# MSS_CTRL_MSS_CTRL register map
Vendor: Texas Instruments
Registers are 32-bit, read-only, reset 0x0 unless marked. A register's access mark holds for its fields unless they carry their own. Offsets are as the file gives them; [hi:lo] are bit positions; {n}, {i} and the like mark numbered series; 'fields as' and 'values as' point back to an identical list.

## MSS_CTRL_MSS_CTRL (part 2 of 5)
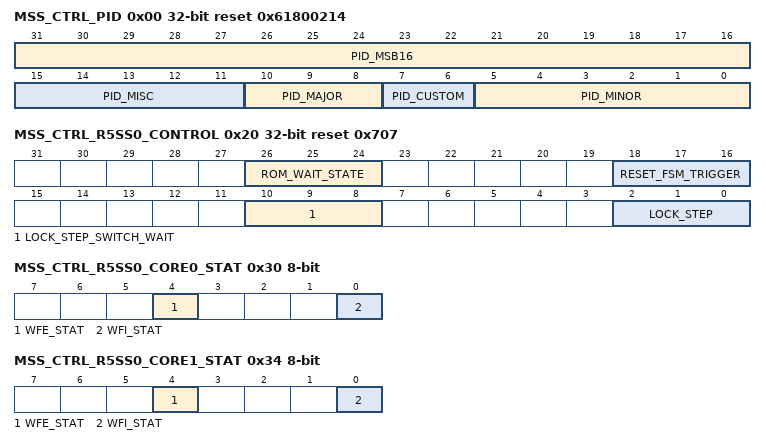
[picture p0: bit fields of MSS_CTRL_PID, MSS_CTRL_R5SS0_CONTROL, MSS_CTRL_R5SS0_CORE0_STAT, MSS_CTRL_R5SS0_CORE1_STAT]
0x00 MSS_CTRL_PID reset 0x61800214
  [31:16] PID_MSB16 — Not Defined
  [15:11] PID_MISC — Not Defined
  [10:8] PID_MAJOR — Not Defined
  [7:6] PID_CUSTOM — Not Defined
  [5:0] PID_MINOR — Not Defined
0x20 MSS_CTRL_R5SS0_CONTROL rw reset 0x707
  [26:24] ROM_WAIT_STATE — writing '111' enables a single cycle wait state with respect to CR5A_clk for rom access.This needs to be set when R5 clock is at 400MHZ and Interconnect-clk is at 200MHZ. (because it is a timing issue in this scenario)
  [18:16] RESET_FSM_TRIGGER — Write pulse bit field:writing 3'b111 will trigger the reset FSM. Reset FSM ensures reset to R5SS and inturn ensures the latching of lock_step and also mem_swap bit
  [10:8] LOCK_STEP_SWITCH_WAIT — writing 3'b111 ensures switch happens only after R5SS reset. Orelse it will be a immediate switch.
  [2:0] LOCK_STEP — writing 3'b000 ensures R5 to be in Dual-Core mode. Note: The change happens after the R5SS reset assertion if R5_CONTROL_lock_step_switch_wait is set. Or else the switiching to Dual-core happens on the fly.
0x24 MSS_CTRL_R5SS0_CORE0_HALT 8-bit rw reset 0x7
  [2:0] HALT — writing '000' will unhalt CR5A. This register should be written only once.
0x28 MSS_CTRL_R5SS0_CORE1_HALT 8-bit rw reset 0x7
  [2:0] HALT — writing '000' will unhalt for CR5B. This register should be written only once.
0x2C MSS_CTRL_R5SS0_STATUS_REG 8-bit
  [8] LOCK_STEP — Reading 1: confirms R5SS is in lockstep mode. Reading 0: confirms R5SS is in Dual-core mode.
  [0] MEMSWAP — reading 1: confirms ROM is Eclipsed from with RAM for R5.
0x30 MSS_CTRL_R5SS0_CORE0_STAT 8-bit
  [4] WFE_STAT — WFE Status
  [0] WFI_STAT — WFI Status
0x34 MSS_CTRL_R5SS0_CORE1_STAT 8-bit
  [4] WFE_STAT — WFE Status
  [0] WFI_STAT — WFI Status
0x38 MSS_CTRL_R5SS0_FORCE_WFI 8-bit rw
  [2:0] CR5_WFI_OVERIDE — writing 3'b111 will force the wfi signals of R5SS to 1
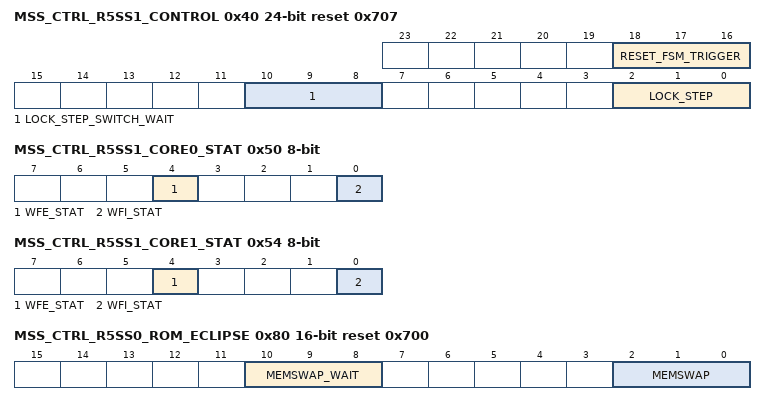
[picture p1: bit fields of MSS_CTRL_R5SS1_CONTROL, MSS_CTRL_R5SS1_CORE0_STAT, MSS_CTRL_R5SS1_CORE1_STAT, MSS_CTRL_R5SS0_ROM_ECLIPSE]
0x40 MSS_CTRL_R5SS1_CONTROL 24-bit rw reset 0x707
  [18:16] RESET_FSM_TRIGGER — Write pulse bit field:writing 3'b111 will trigger the reset FSM. Reset FSM ensures reset to R5SS and inturn ensures the latching of lock_step and also mem_swap bit
  [10:8] LOCK_STEP_SWITCH_WAIT — writing 3'b111 ensures switch happens only after R5SS reset. Orelse it will be a immediate switch.
  [2:0] LOCK_STEP — writing 3'b000 ensures R5 to be in Dual-Core mode. Note: The change happens after the R5SS reset assertion if R5_CONTROL_lock_step_switch_wait is set. Or else the switiching to Dual-core happens on the fly.
0x44 MSS_CTRL_R5SS1_CORE0_HALT 8-bit rw reset 0x7
  fields as MSS_CTRL_R5SS0_CORE0_HALT
0x48 MSS_CTRL_R5SS1_CORE1_HALT 8-bit rw reset 0x7
  fields as MSS_CTRL_R5SS0_CORE1_HALT
0x4C MSS_CTRL_R5SS1_STATUS_REG 8-bit
  [8] LOCK_STEP — Reading 1: confirms R5SS is in lockstep mode. Reading 0: confirms R5SS is in Dual-core mode.
0x50 MSS_CTRL_R5SS1_CORE0_STAT 8-bit
  [4] WFE_STAT — WFE Status
  [0] WFI_STAT — WFI Status
0x54 MSS_CTRL_R5SS1_CORE1_STAT 8-bit
  [4] WFE_STAT — WFE Status
  [0] WFI_STAT — WFI Status
0x58 MSS_CTRL_R5SS1_FORCE_WFI 8-bit rw
  fields as MSS_CTRL_R5SS0_FORCE_WFI
0x80 MSS_CTRL_R5SS0_ROM_ECLIPSE 16-bit rw reset 0x700
  [10:8] MEMSWAP_WAIT — writing 3'b111 ensures ROM-Eclipsing happens only after R5SS reset. Orelse it will be a immediate change.
  [2:0] MEMSWAP — writing '111' ensures eclipsing of CR5A_ROM immediately if memswap_wait is not set. If memswap_wait is set then ROM is eclipsed after R5SS reset assertion.
0x90 MSS_CTRL_R5SS0_TEINIT size not given rw
  [0] TEINIT — Exception handling state at reset. 0-ARM 1-Thumb
0x94 MSS_CTRL_R5SS1_TEINIT size not given rw
  [0] TEINIT — Exception handling state at reset. 0-ARM 1-Thumb
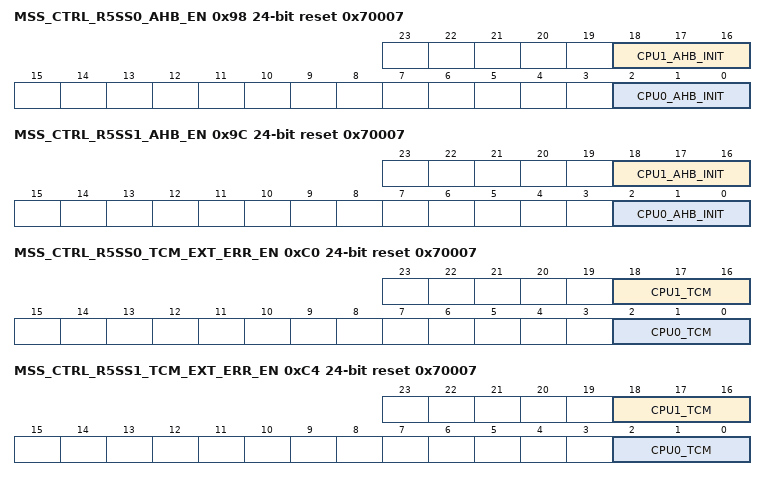
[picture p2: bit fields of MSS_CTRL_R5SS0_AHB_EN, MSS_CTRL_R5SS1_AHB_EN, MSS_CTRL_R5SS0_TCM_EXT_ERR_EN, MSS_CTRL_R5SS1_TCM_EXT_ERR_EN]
0x98 MSS_CTRL_R5SS0_AHB_EN 24-bit rw reset 0x70007
  [18:16] CPU1_AHB_INIT — Ti internal Register. Modifying this register is not recommendedSignal decides whehter ahb interface is enabled or not.
  [2:0] CPU0_AHB_INIT — Ti internal Register. Modifying this register is not recommendedSignal decides whehter ahb interface is enabled or not.
0x9C MSS_CTRL_R5SS1_AHB_EN 24-bit rw reset 0x70007
  fields as MSS_CTRL_R5SS0_AHB_EN
0xA0 MSS_CTRL_R5SS0_CORE0_AHB_BASE 24-bit rw reset 0x50000
  [19:0] AHB_BASE — Ti internal Register. Modifying this register is not recommendedDecides the base address of ahb region
0xA4 MSS_CTRL_R5SS1_CORE0_AHB_BASE 24-bit rw reset 0x50000
  fields as MSS_CTRL_R5SS0_CORE0_AHB_BASE
0xA8 MSS_CTRL_R5SS0_CORE0_AHB_SIZE 8-bit rw reset 0x13
  [4:0] AHB_SIZE — Ti internal Register. Modifying this register is not recommendedCode for selecting size for ahb.b00011 4KBb00100 8KBb00101 16KBb00110 32KBb00111 64KBb01000 128KBb01001 256KBb01010 512KBb01011 1MBb01100 2MBb01101 4MBb01110 8MBb01111 16MBb10000 32MBb10001 64MBb10010 128MBb10011 256MBb10100 512MBb10101 1GBb10110 2GBb10111 4GB
0xAC MSS_CTRL_R5SS1_CORE0_AHB_SIZE 8-bit rw reset 0x13
  fields as MSS_CTRL_R5SS0_CORE0_AHB_SIZE
0xB0 MSS_CTRL_R5SS0_CORE1_AHB_BASE 24-bit rw reset 0x50000
  fields as MSS_CTRL_R5SS0_CORE0_AHB_BASE
0xB4 MSS_CTRL_R5SS1_CORE1_AHB_BASE 24-bit rw reset 0x50000
  fields as MSS_CTRL_R5SS0_CORE0_AHB_BASE
0xB8 MSS_CTRL_R5SS0_CORE1_AHB_SIZE 8-bit rw reset 0x13
  fields as MSS_CTRL_R5SS0_CORE0_AHB_SIZE
0xBC MSS_CTRL_R5SS1_CORE1_AHB_SIZE 8-bit rw reset 0x13
  fields as MSS_CTRL_R5SS0_CORE0_AHB_SIZE
0xC0 MSS_CTRL_R5SS0_TCM_EXT_ERR_EN 24-bit rw reset 0x70007
  [18:16] CPU1_TCM — Ti internal Register. Modifying this register is not recommendedTCMs external error enable. Tie each bit high to enable the external error signal for each TCM at reset
  [2:0] CPU0_TCM — Ti internal Register. Modifying this register is not recommendedTCMs external error enable. Tie each bit high to enable the external error signal for each TCM at reset
0xC4 MSS_CTRL_R5SS1_TCM_EXT_ERR_EN 24-bit rw reset 0x70007
  fields as MSS_CTRL_R5SS0_TCM_EXT_ERR_EN
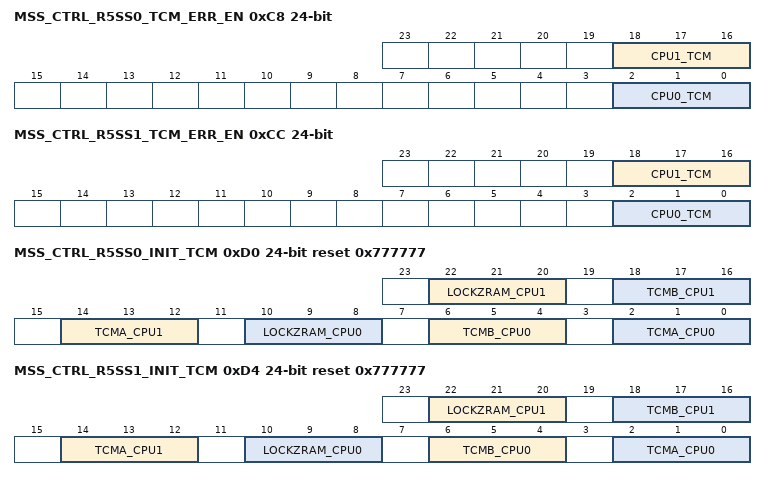
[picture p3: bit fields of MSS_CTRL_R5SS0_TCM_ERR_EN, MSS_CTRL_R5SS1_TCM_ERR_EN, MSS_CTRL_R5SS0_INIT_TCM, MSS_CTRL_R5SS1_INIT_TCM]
0xC8 MSS_CTRL_R5SS0_TCM_ERR_EN 24-bit rw
  [18:16] CPU1_TCM — Ti internal Register. Modifying this register is not recommendedTCMs ECC check enable. Tie each bit high to enable ECC checking on appropraite TCM
  [2:0] CPU0_TCM — Ti internal Register. Modifying this register is not recommendedTCMs ECC check enable. Tie each bit high to enable ECC checking on appropraite TCM
0xCC MSS_CTRL_R5SS1_TCM_ERR_EN 24-bit rw
  fields as MSS_CTRL_R5SS0_TCM_ERR_EN
0xD0 MSS_CTRL_R5SS0_INIT_TCM 24-bit rw reset 0x777777
  [22:20] LOCKZRAM_CPU1 — Ti internal Register. Modifying this register is not recommendedWhen HIGH ATCM base address at reset is 0x0 when LOW BTCM base address at reset is 0x0
  [18:16] TCMB_CPU1 — Ti internal Register. Modifying this register is not recommendedWhen HIGH enables BTCM interface out of reset
  [14:12] TCMA_CPU1 — Ti internal Register. Modifying this register is not recommendedWhen HIGH enables ATCM interface out of reset
  [10:8] LOCKZRAM_CPU0 — Ti internal Register. Modifying this register is not recommendedWhen HIGH ATCM base address at reset is 0x0 when LOW BTCM base address at reset is 0x0
  [6:4] TCMB_CPU0 — Ti internal Register. Modifying this register is not recommendedWhen HIGH enables BTCM interface out of reset
  [2:0] TCMA_CPU0 — Ti internal Register. Modifying this register is not recommendedWhen HIGH enables ATCM interface out of reset
0xD4 MSS_CTRL_R5SS1_INIT_TCM 24-bit rw reset 0x777777
  fields as MSS_CTRL_R5SS0_INIT_TCM
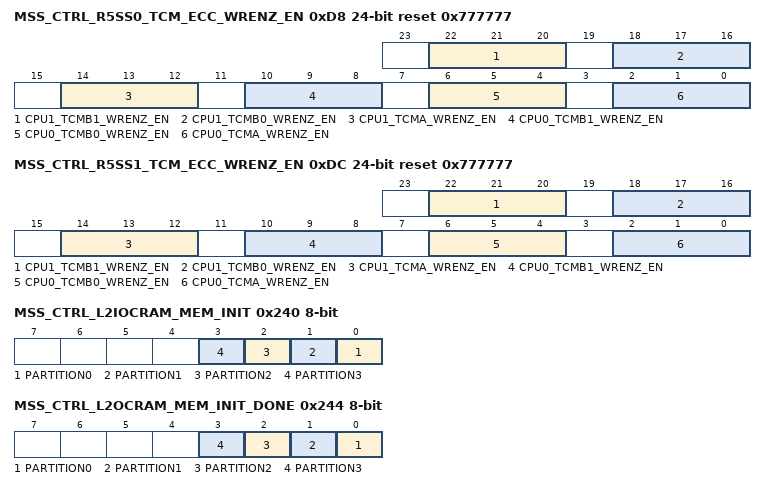
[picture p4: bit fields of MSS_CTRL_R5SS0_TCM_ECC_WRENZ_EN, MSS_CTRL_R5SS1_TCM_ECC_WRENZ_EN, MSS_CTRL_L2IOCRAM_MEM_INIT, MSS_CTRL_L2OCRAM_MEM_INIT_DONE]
0xD8 MSS_CTRL_R5SS0_TCM_ECC_WRENZ_EN 24-bit rw reset 0x777777
  [22:20] CPU1_TCMB1_WRENZ_EN — writing '000' blocks the writes to ECC-bits of TCMB0-RAM of CR5B.Writing '111' unblocks the writes to ECC-bits of TCMB1-RAM of CR5B
  [18:16] CPU1_TCMB0_WRENZ_EN — writing '000' blocks the writes to ECC-bits of TCMB0-RAM of CR5B.Writing '111' unblocks the writes to ECC-bits of TCMB0-RAM of CR5B
  [14:12] CPU1_TCMA_WRENZ_EN — writing '000' blocks the writes to ECC-bits of TCMA-RAM of CR5B.Writing '111' unblocks the writes to ECC-bits of TCMA-RAM of CR5B
  [10:8] CPU0_TCMB1_WRENZ_EN — writing '000' blocks the writes to ECC-bits of TCMB0-RAM of CR5A.Writing '111' unblocks the writes to ECC-bits of TCMB1-RAM of CR5A
  [6:4] CPU0_TCMB0_WRENZ_EN — writing '000' blocks the writes to ECC-bits of TCMB0-RAM of CR5A.Writing '111' unblocks the writes to ECC-bits of TCMB0-RAM of CR5A
  [2:0] CPU0_TCMA_WRENZ_EN — writing '000' blocks the writes to ECC-bits of TCMA-RAM of CR5A.Writing '111' unblocks the writes to ECC-bits of TCMA-RAM of CR5A
0xDC MSS_CTRL_R5SS1_TCM_ECC_WRENZ_EN 24-bit rw reset 0x777777
  fields as MSS_CTRL_R5SS0_TCM_ECC_WRENZ_EN
{0x100+4i} MSS_CTRL_BOOT_INFO_REG{i} rw (i=0..7)
  [31:0] CONFIG — Reserved Register for Software use
0x200 MSS_CTRL_R5SS0_ATCM_MEM_INIT size not given rw
  [0] MEM_INIT — Write_pulse bit field:Writing 1'b1 will start initializing the ATCM banks of CR5A/B. Value in each row is initialized to 0x0C_0000_0000
0x204 MSS_CTRL_R5SS0_ATCM_MEM_INIT_DONE size not given rw
  [0] MEM_INIT_DONE — This field will be high once initialization of ATCM banks is finished. Writing '1' would clear the bit.
0x208 MSS_CTRL_R5SS0_ATCM_MEM_INIT_STATUS size not given
  [0] MEM_STATUS — 1'b0: No initialization is happening for ATCM banks of CR5A/B1'b1: Initialization is in progress for ATCM banks of CR5A/B
0x210 MSS_CTRL_R5SS0_BTCM_MEM_INIT size not given rw
  [0] MEM_INIT — Write_pulse bit field:Writing 1'b1 will start initializing the B0/1TCM banks of CR5A/B
0x214 MSS_CTRL_R5SS0_BTCM_MEM_INIT_DONE size not given rw
  [0] MEM_INIT_DONE — This field will be high once initialization of B0/1TCM banks is finished. Writing '1' would clear the bit.
0x218 MSS_CTRL_R5SS0_BTCM_MEM_INIT_STATUS size not given
  [0] MEM_STATUS — 1'b0: No initialization is happening for B0/1TCM banks of CR5A/B1'b1: Initialization is in progress for B0/1TCM banks of CR5A/B
0x220 MSS_CTRL_R5SS1_ATCM_MEM_INIT size not given rw
  fields as MSS_CTRL_R5SS0_ATCM_MEM_INIT
0x224 MSS_CTRL_R5SS1_ATCM_MEM_INIT_DONE size not given rw
  fields as MSS_CTRL_R5SS0_ATCM_MEM_INIT_DONE
0x228 MSS_CTRL_R5SS1_ATCM_MEM_INIT_STATUS size not given
  fields as MSS_CTRL_R5SS0_ATCM_MEM_INIT_STATUS
0x230 MSS_CTRL_R5SS1_BTCM_MEM_INIT size not given rw
  fields as MSS_CTRL_R5SS0_BTCM_MEM_INIT
0x234 MSS_CTRL_R5SS1_BTCM_MEM_INIT_DONE size not given rw
  fields as MSS_CTRL_R5SS0_BTCM_MEM_INIT_DONE
0x238 MSS_CTRL_R5SS1_BTCM_MEM_INIT_STATUS size not given
  fields as MSS_CTRL_R5SS0_BTCM_MEM_INIT_STATUS
0x240 MSS_CTRL_L2IOCRAM_MEM_INIT 8-bit rw
  [n] PARTITION{n} (n=0..3) — Write_pulse bit field:Writing 1'b1 will start initializing the L2 Bank{n}. Value in each row is initialized to 0x0
0x244 MSS_CTRL_L2OCRAM_MEM_INIT_DONE 8-bit rw
  [n] PARTITION{n} (n=0..3) — This field will be high once intialization of L2 bank{n} is finished. Writing '1' would clear the bit
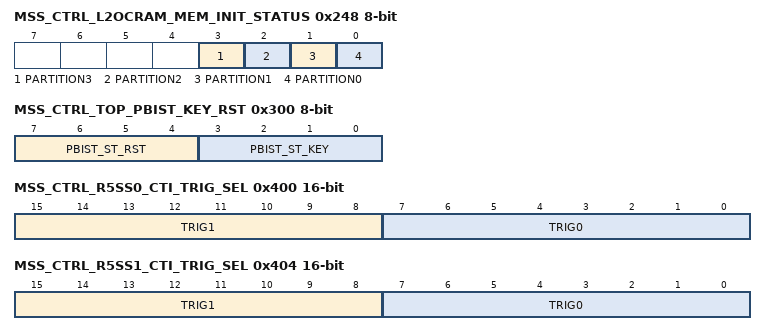
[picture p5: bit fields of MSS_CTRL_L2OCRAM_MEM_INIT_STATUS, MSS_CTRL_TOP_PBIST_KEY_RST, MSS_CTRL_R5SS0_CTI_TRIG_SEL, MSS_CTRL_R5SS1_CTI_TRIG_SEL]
0x248 MSS_CTRL_L2OCRAM_MEM_INIT_STATUS 8-bit
  [3] PARTITION3 — 1'b0: No initialization is happening for L2 bank31'b1: Initialization is in progress for L2 bank3
  [2] PARTITION2 — 1'b0: No initialization is happening for L2 bank2 1'b1: Initialization is in progress for L2 bank2
  [1] PARTITION1 — 1'b0: No initialization is happening for L2 bank11'b1: Initialization is in progress for L2 bank1
  [0] PARTITION0 — 1'b0: No initialization is happening for L2 bank0 1'b1: Initialization is in progress for L2 bank0
0x250 MSS_CTRL_MAILBOXRAM_MEM_INIT size not given rw
  [0] MEM0_INIT — Write_pulse bit field:Writing 1'b1 will start initializing the MSS_MBOX. Value in each row is initialized to 0x0
0x254 MSS_CTRL_MAILBOXRAM_MEM_INIT_DONE size not given rw
  [0] MEM0_DONE — This field will be high once intialization of MSS_MBOX is finished. Writing '1' would clear the bit
0x258 MSS_CTRL_MAILBOXRAM_MEM_INIT_STATUS size not given
  [0] MEM0_STATUS — 1'b0: No initialization is happening for MSS_MBOX 1'b1: Initialization is in progress for MSS_MBOX
0x260 MSS_CTRL_TPCC_MEM_INIT size not given rw
  [0] TPCC_A_MEMINIT_START — Write_pulse bit field:Writing 1'b1 will start initializing the MSS_TPCCA
0x264 MSS_CTRL_TPCC_MEM_INIT_DONE size not given rw
  [0] TPCC_A_MEMINIT_DONE — This field will be high once intialization of MSS_TPCCA is finished. Writing '1' would clear the bit
0x268 MSS_CTRL_TPCC_MEMINIT_STATUS size not given
  [0] TPCC_A_MEMINIT_STATUS — 1'b0: No initialization is happening for MSS_TPCCA1'b1: Initialization is in progress for MSS_TPCCB
0x300 MSS_CTRL_TOP_PBIST_KEY_RST 8-bit rw
  [7:4] PBIST_ST_RST — MSS PBIST controller will be brought out of reset when value is 0xA
  [3:0] PBIST_ST_KEY — Top PBIST Selftest Key. Valid value is 0x5
{0x304+4i} MSS_CTRL_TOP_PBIST_REG{i} rw (i=0..2)
  [31:0] PBIST_REG — Not Defined
0x400 MSS_CTRL_R5SS0_CTI_TRIG_SEL 16-bit rw
  [15:8] TRIG1 — Used for selecting the trigger source for 1st trigger of MSS_R5SS
  [7:0] TRIG0 — Used for selecting the trigger source for 0th trigger of MSS_R5SS
0x404 MSS_CTRL_R5SS1_CTI_TRIG_SEL 16-bit rw
  fields as MSS_CTRL_R5SS0_CTI_TRIG_SEL
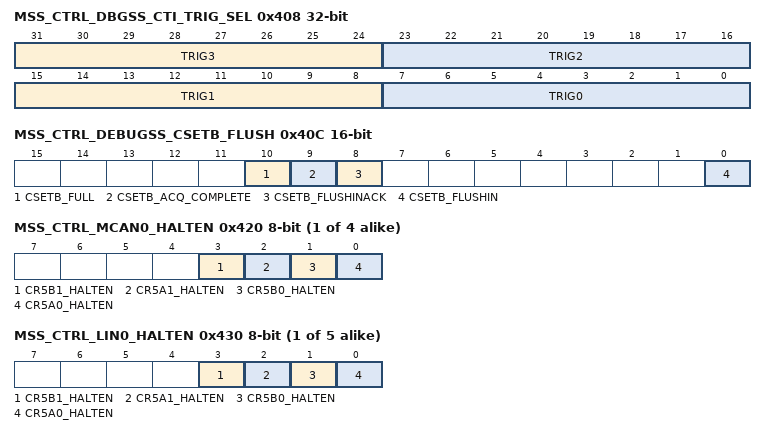
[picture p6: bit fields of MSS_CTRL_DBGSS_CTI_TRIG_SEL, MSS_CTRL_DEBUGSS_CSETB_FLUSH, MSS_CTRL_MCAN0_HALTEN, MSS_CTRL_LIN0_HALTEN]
0x408 MSS_CTRL_DBGSS_CTI_TRIG_SEL rw
  [31:24] TRIG3 — Used for selecting the trigger source for 3rd trigger of ONE_MCU_CTI
  [23:16] TRIG2 — Used for selecting the trigger source for 2nd trigger of ONE_MCU_CTI
  [15:8] TRIG1 — Used for selecting the trigger source for 1st trigger of ONE_MCU_CTI
  [7:0] TRIG0 — Used for selecting the trigger source for 0th trigger of ONE_MCU_CTI
0x40C MSS_CTRL_DEBUGSS_CSETB_FLUSH 16-bit access per field
  [10] CSETB_FULL ro — When HIGH indicates that the ETB RAM has overflowed or wrapped around to address zero
  [9] CSETB_ACQ_COMPLETE ro — When HIGH, indicates that trace acquisition is complete by ETB, that is, the trigger counter is at zero
  [8] CSETB_FLUSHINACK ro — Return acknowledgement to CSETBFLUSHIN
  [0] CSETB_FLUSHIN rw — External control used to assert the ATB signal AFVALIDS and drain any historical FIFO information on the bus
0x410 MSS_CTRL_DEBUGSS_STM_NSGUAREN 16-bit rw
  [10] ENABLE — Non secure guarenteed access control0:Access does not stall the CPU. Trace not guarenteed1: Access may stall. Trace guarenteed
{0x420+4i} MSS_CTRL_MCAN{i}_HALTEN 8-bit rw (i=0..3)
  [3] CR5B1_HALTEN — 1'b0: IP Halt disabled with corresponding CPU halt1'b1: IP Halt enabled with corresponding CPU halt
  [2] CR5A1_HALTEN — 1'b0: IP Halt disabled with corresponding CPU halt1'b1: IP Halt enabled with corresponding CPU halt
  [1] CR5B0_HALTEN — 1'b0: IP Halt disabled with corresponding CPU halt1'b1: IP Halt enabled with corresponding CPU halt
  [0] CR5A0_HALTEN — 1'b0: IP Halt disabled with corresponding CPU halt1'b1: IP Halt enabled with corresponding CPU halt
{0x430+4i} MSS_CTRL_LIN{i}_HALTEN 8-bit rw (i=0..4)
  fields as MSS_CTRL_MCAN0_HALTEN
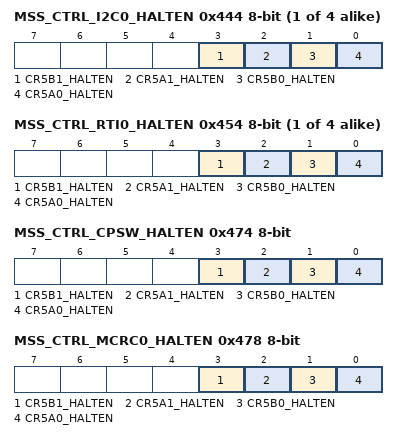
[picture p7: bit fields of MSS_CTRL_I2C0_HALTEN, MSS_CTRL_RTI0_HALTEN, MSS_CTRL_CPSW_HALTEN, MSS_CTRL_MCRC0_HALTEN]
{0x444+4i} MSS_CTRL_I2C{i}_HALTEN 8-bit rw (i=0..3)
  fields as MSS_CTRL_MCAN0_HALTEN
{0x454+4i} MSS_CTRL_RTI{i}_HALTEN 8-bit rw (i=0..3)
  fields as MSS_CTRL_MCAN0_HALTEN
0x474 MSS_CTRL_CPSW_HALTEN 8-bit rw
  fields as MSS_CTRL_MCAN0_HALTEN
0x478 MSS_CTRL_MCRC0_HALTEN 8-bit rw
  fields as MSS_CTRL_MCAN0_HALTEN
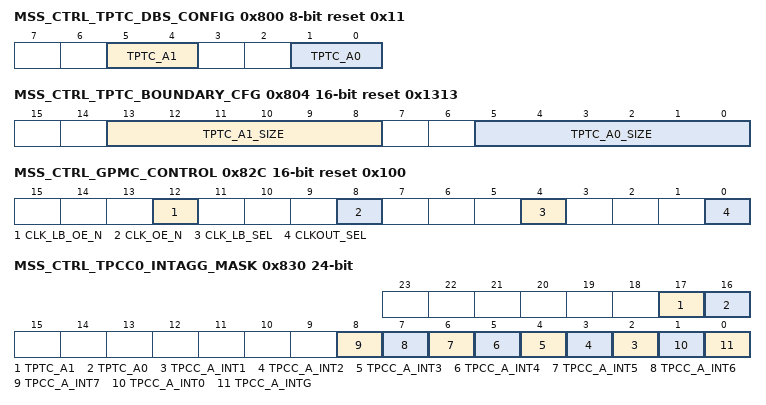
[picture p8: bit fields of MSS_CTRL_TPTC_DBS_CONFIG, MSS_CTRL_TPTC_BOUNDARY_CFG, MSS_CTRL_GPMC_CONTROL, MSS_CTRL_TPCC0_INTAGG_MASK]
0x800 MSS_CTRL_TPTC_DBS_CONFIG 8-bit rw reset 0x11
  [5:4] TPTC_A1 — Default burst size tieoff value for TPTC_A1
  [1:0] TPTC_A0 — Default burst size tieoff value for TPTC_A0
0x804 MSS_CTRL_TPTC_BOUNDARY_CFG 16-bit rw reset 0x1313
  [13:8] TPTC_A1_SIZE — 6 bit signal used for deciding the boundary crossing size for CID-RID-SID reordering of MSS_TPTC_A1Example: writing 6'd19 decidies boundary to be 2^19 i.e. 512 KB
  [5:0] TPTC_A0_SIZE — 6 bit signal used for deciding the boundary crossing size for CID-RID-SID reordering of MSS_TPTC_A0Example: writing 6'd19 decidies boundary to be 2^19 i.e. 512 KB
0x808 MSS_CTRL_TPTC_XID_REORDER_CFG 8-bit rw
  [8] TPTC_A1_DISABLE — writing 1'b1 will disable the CID-RID-SID reodering feature for MSS_TPTC_A1
  [0] TPTC_A0_DISABLE — writing 1'b1 will disable the CID-RID-SID reodering feature for MSS_TPTC_A0
0x810 MSS_CTRL_CPSW_CONTROL 24-bit rw reset 0x1000100
  [24] RGMII2_ID_MODE — Internal delay mode for port 2. Only for TX0 : ID mode is disabled1 : ID mode is enabled
  [22] RMII2_REF_CLK_SEL — To select the rmii_ref_clk loopback mux output either from PAD or from MSS_RCM. Write 0 to get clock will be from IO pad(pad loopback). Write 1 to get clock from internal loopback.
  [20] RMII2_REF_CLK_OE_N — RMII_REF_CLK IO Output enable control0: Output enable1: Output Disable
  [18:16] PORT2_MODE_SEL — Port 2 Interface 000 = MII001 = RMII010 = RGMII011 - 111 = Not Supported
  [8] RGMII1_ID_MODE — Internal delay mode for port 1. Only for TX0 : ID mode is disabled1 : ID mode is enabled
  [6] RMII1_REF_CLK_SEL — To select the rmii_ref_clk loopback mux output either from PAD or from MSS_RCM. Write 0 to get clock will be from IO pad(pad loopback). Write 1 to get clock from internal source
  [4] RMII1_REF_CLK_OE_N — RMII_REF_CLK IO Output enable control0: Output enable1: Output Disable
  [2:0] PORT1_MODE_SEL — Port 1 Interface 000 = MII001 = RMII010 = RGMII011 - 111 = Not Supported
0x814 MSS_CTRL_QSPI_CONFIG 8-bit rw
  [2:0] EXT_CLK — Write 3'b111 to external clock as QSPI baud clock source needed for DFT IO char.
0x818 MSS_CTRL_ICSSM_IDLE_CONTROL size not given rw reset 0x1
  [0] NOGATE — Writing 1'b0 will enable local auto-clock gating (lower power) at IP level with increase in access/functional latency. Following IPs are controlled with this signalICSSM
0x81C MSS_CTRL_ICSSM_PRU0_GPI_SEL rw
  [29:0] SEL — GPI or PWMXBar select for ICSM Port00: GPI1: PWMXBAR
0x820 MSS_CTRL_ICSSM_PRU1_GPI_SEL rw
  [29:0] SEL — GPI or PWMXBar select for ICSM Port00: GPI1: PWMXBAR
0x824 MSS_CTRL_ICSSM_PRU0_GPIO_OUT_CTRL rw
  [29:0] OUTDISABLE — GPO output disable for ICSSM Port 0 IO. Disable output for using the pin as input. Each Bit maps to the corresponding bit in the IO0: Output Enable1: Output Disable
0x828 MSS_CTRL_ICSSM_PRU1_GPIO_OUT_CTRL rw
  [29:0] OUTDISABLE — GPO output disable for ICSSM Port 1 IO. Disable output for using the pin as input. Each Bit maps to the corresponding bit in the IO0: Output Enable1: Output Disable
0x82C MSS_CTRL_GPMC_CONTROL 16-bit rw reset 0x100
  [12] CLK_LB_OE_N — GPMC_CLK_LB oe_n1: GPMC_dev_clk is driven to pad0: GPMC_dev_clk is not driven to pad
  [8] CLK_OE_N — GPMC_CLKOUT oe_n1: GPMC_dev_clk mux output is driven to pad0: GPMC_dev_clk mux output is not driven to pad
  [4] CLK_LB_SEL — GPMC_CLK_LB sel0: GPMC_CLK_LB pad clock1: GPMC_CLK pad clock
  [0] CLKOUT_SEL — GPMC_CLKOUT sel0: GPMC_func_clock1: GPMC_dev clock
0x830 MSS_CTRL_TPCC0_INTAGG_MASK 24-bit rw
  [17] TPTC_A1 — Mask Interrupt from TPTC A1 to aggregated Interrupt MSS_TPCC_A_INTAGG1 : Interrupt is Masked0 : Interrupt is Unmasked
  [16] TPTC_A0 — Mask Interrupt from TPTC A0 to aggregated Interrupt MSS_TPCC_A_INTAGG1 : Interrupt is Masked0 : Interrupt is Unmasked
  [n+1] TPCC_A_INT{n} (n=1..7) — Mask Interrupt from MSS_TPCC_A to aggregated Interrupt MSS_TPCC_A_INTAGG1 : Interrupt is Masked0 : Interrupt is Unmasked
  [1] TPCC_A_INT0 — Mask Interrupt from TPCC A to aggregated Interrupt MSS_TPCC_A_INTAGG1 : Interrupt is Masked0 : Interrupt is Unmasked
  [0] TPCC_A_INTG — Mask Interrupt from MSS_TPCC_A to aggregated Interrupt MSS_TPCC_A_INTAGG1 : Interrupt is Masked0 : Interrupt is Unmasked
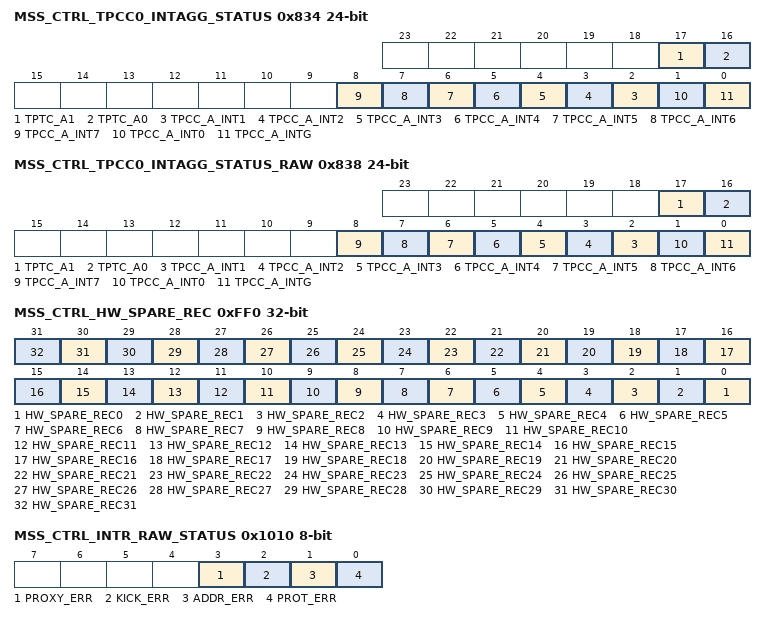
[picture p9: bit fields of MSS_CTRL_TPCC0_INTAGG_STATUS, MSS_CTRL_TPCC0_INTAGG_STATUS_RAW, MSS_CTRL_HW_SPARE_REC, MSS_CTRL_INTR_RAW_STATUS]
0x834 MSS_CTRL_TPCC0_INTAGG_STATUS 24-bit rw
  [17] TPTC_A1 — Status of Interrupt from TPTC A1. Set only if Interupt is unmasked in MSS_TPCC_A_INTAGG_MASKWrie 0x1 to clear this interrupt.
  [16] TPTC_A0 — Status of Interrupt from TPTC A0. Set only if Interupt is unmasked in MSS_TPCC_A_INTAGG_MASKWrie 0x1 to clear this interrupt.
  [n+1] TPCC_A_INT{n} (n=1..7) — Status of Interrupt from MSS_TPCC_A. Set only if Interupt is unmasked in MSS_TPCC_A_INTAGG_MASKWrie 0x1 to clear this interrupt.
  [1] TPCC_A_INT0 — Status of Interrupt from TPCC A Set only if Interupt is unmasked in MSS_TPCC_A_INTAGG_MASKWrie 0x1 to clear this interrupt.
  [0] TPCC_A_INTG — Status of Interrupt from MSS_TPCC_A. Set only if Interupt is unmasked in MSS_TPCC_A_INTAGG_MASKWrie 0x1 to clear this interrupt.
0x838 MSS_CTRL_TPCC0_INTAGG_STATUS_RAW 24-bit rw
  [17] TPTC_A1 — Raw Status of Interrupt from TPTC A1. Set irrespective if the Interupt is masked or unmasked in MSS_TPCC_A_INTAGG_MASK
  [16] TPTC_A0 — Raw Status of Interrupt from TPTC A0. Set irrespective if the Interupt is masked or unmasked in MSS_TPCC_A_INTAGG_MASK
  [n+1] TPCC_A_INT{n} (n=1..7) — Raw Status of Interrupt from MSS_TPCC_A. Set irrespective if the Interupt is masked or unmasked in MSS_TPCC_C_INTAGG_MASK
  [1] TPCC_A_INT0 — Raw Status of Interrupt from TPCC A. Set irrespective if the Interupt is masked or unmasked in MSS_TPCC_A_INTAGG_MASK
  [0] TPCC_A_INTG — Raw Status of Interrupt from MSS_TPCC_A. Set irrespective if the Interupt is masked or unmasked in MSS_TPCC_C_INTAGG_MASK
{0xFD0+4i} MSS_CTRL_HW_SPARE_RW{i} rw (i=0..3)
  [31:0] HW_SPARE_RW{i} — Reserved for HW R&D
{0xFE0+4i} MSS_CTRL_HW_SPARE_RO{i} (i=0..3)
  [31:0] HW_SPARE_RO{i} — Reserved for HW R&D
0xFF0 MSS_CTRL_HW_SPARE_REC rw
  [n] HW_SPARE_REC{n} (n=0..31) — Reserved for HW R&D
0x1008 MSS_CTRL_LOCK0_KICK0 rw
  [31:0] LOCK0_KICK0 — - KICK0 component
0x100C MSS_CTRL_LOCK0_KICK1 rw
  [31:0] LOCK0_KICK1 — - KICK1 component
0x1010 MSS_CTRL_INTR_RAW_STATUS 8-bit rw
  [3] PROXY_ERR — Proxy0 access violation error. Raw status is read. Write a 1 to set the status. Writing a 0 has no effect.
  [2] KICK_ERR — Kick access violation error. Raw status is read. Write a 1 to set the status. Writing a 0 has no effect.
  [1] ADDR_ERR — Addressing violation error. Raw status is read. Write a 1 to set the status. Writing a 0 has no effect.
  [0] PROT_ERR — Protection violation error. Raw status is read. Write a 1 to set the status. Writing a 0 has no effect.
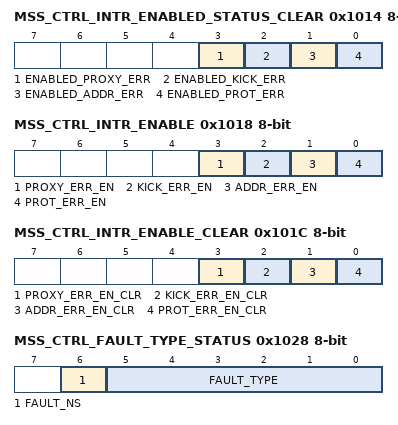
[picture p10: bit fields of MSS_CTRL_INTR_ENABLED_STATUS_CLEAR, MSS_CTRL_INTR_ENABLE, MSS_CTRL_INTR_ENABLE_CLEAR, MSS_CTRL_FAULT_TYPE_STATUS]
0x1014 MSS_CTRL_INTR_ENABLED_STATUS_CLEAR 8-bit rw
  [3] ENABLED_PROXY_ERR — Proxy0 access violation error. Enabled status is read. Write a 1 to clear the status. Writing a 0 has no effect.
  [2] ENABLED_KICK_ERR — Kick access violation error. Enabled status is read. Write a 1 to clear the status. Writing a 0 has no effect.
  [1] ENABLED_ADDR_ERR — Addressing violation error. Enabled status is read. Write a 1 to clear the status. Writing a 0 has no effect.
  [0] ENABLED_PROT_ERR — Protection violation error. Enabled status is read. Write a 1 to clear the status. Writing a 0 has no effect.
0x1018 MSS_CTRL_INTR_ENABLE 8-bit rw
  [3] PROXY_ERR_EN — Proxy0 access violation error enable. Write a 1 to set the enable. Writing a 0 has no effect.
  [2] KICK_ERR_EN — Kick access violation error enable. Write a 1 to set the enable. Writing a 0 has no effect.
  [1] ADDR_ERR_EN — Addressing violation error enable. Write a 1 to set the enable. Writing a 0 has no effect.
  [0] PROT_ERR_EN — Protection violation error enable. Write a 1 to set the enable. Writing a 0 has no effect.
0x101C MSS_CTRL_INTR_ENABLE_CLEAR 8-bit rw
  [3] PROXY_ERR_EN_CLR — Proxy0 access violation error enable clear. Write a 1 to clear the enable. Writing a 0 has no effect.
  [2] KICK_ERR_EN_CLR — Kick access violation error enable clear. Write a 1 to clear the enable. Writing a 0 has no effect.
  [1] ADDR_ERR_EN_CLR — Addressing violation error enable clear. Write a 1 to clear the enable. Writing a 0 has no effect.
  [0] PROT_ERR_EN_CLR — Protection violation error enable clear. Write a 1 to clear the enable. Writing a 0 has no effect.
0x1020 MSS_CTRL_EOI 8-bit rw
  [7:0] EOI_VECTOR — EOI vector value. Write this with interrupt distribution value in the chip.
0x1024 MSS_CTRL_FAULT_ADDRESS
  [31:0] FAULT_ADDR — Fault Address.
0x1028 MSS_CTRL_FAULT_TYPE_STATUS 8-bit
  [6] FAULT_NS — Non-secure access.
  [5:0] FAULT_TYPE — Fault Type 10_0000 = Supervisor read fault - priv = 1 dir = 1 dtype != 1 01_0000 = Supervisor write fault - priv = 1 dir = 0 00_1000 = Supervisor execute fault - priv = 1 dir = 1 dtype = 1 00_0100 = User read fault - priv = 0 dir = 1 dtype = 1 00_0010 = User write fault - priv = 0 dir = 0 00_0001 = User execute fault - priv = 0 dir = 1 dtype = 1 00_0000 = No fault
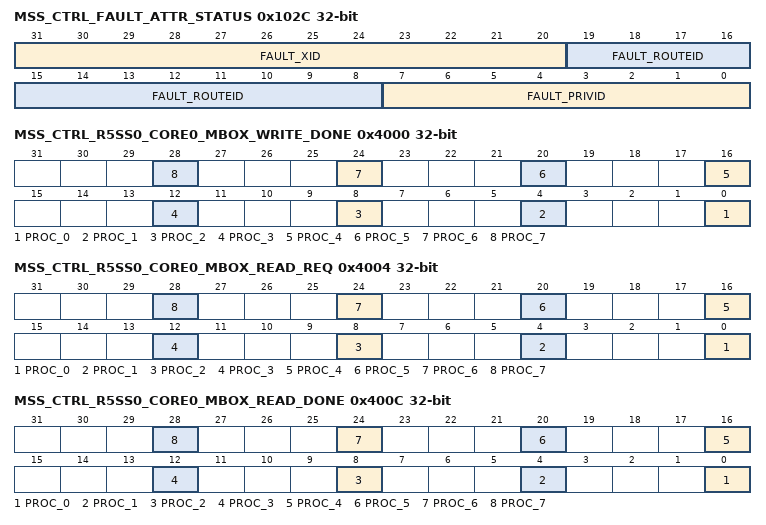
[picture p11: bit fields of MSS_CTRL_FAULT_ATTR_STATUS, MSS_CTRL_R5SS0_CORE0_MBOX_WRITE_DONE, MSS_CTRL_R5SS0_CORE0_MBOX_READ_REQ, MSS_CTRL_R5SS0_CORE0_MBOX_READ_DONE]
0x102C MSS_CTRL_FAULT_ATTR_STATUS
  [31:20] FAULT_XID — XID.
  [19:8] FAULT_ROUTEID — Route ID.
  [7:0] FAULT_PRIVID — Privilege ID.
0x1030 MSS_CTRL_FAULT_CLEAR size not given wo
  [0] FAULT_CLR — Fault clear. Writing a 1 clears the current fault. Writing a 0 has no effect.
0x4000 MSS_CTRL_R5SS0_CORE0_MBOX_WRITE_DONE rw
  [4n] PROC_{n} (n=0..7) — Write pulse bit field:This register should be written once finishing writing into the mailbox memory of processor {n}
0x4004 MSS_CTRL_R5SS0_CORE0_MBOX_READ_REQ rw
  [4n] PROC_{n} (n=0..7) — This is request from processor {n} to mss_cr5a. Requesting it to read from mailbox.
0x4008 MSS_CTRL_R5SS0_CORE0_MBOX_READ_DONE_ACK 8-bit rw
  [7:0] PROC — Write pulse bit field:For bits 0 to 7:Wrting1'b1 : Generates pulse interrupt to corresponding proc from MSS_CR5
0x400C MSS_CTRL_R5SS0_CORE0_MBOX_READ_DONE rw
  [4n] PROC_{n} (n=0..7) — This register should be written once finishing reading from CR5A's mailbox written by proc {n}
0x4010 MSS_CTRL_R5SS0_CORE0_SW_INT size not given rw
  [0] PULSE — Write_pulse bit field:writing 1'b1 to each bit will trigger MSS_SW_INT respectively to CR5A/B.
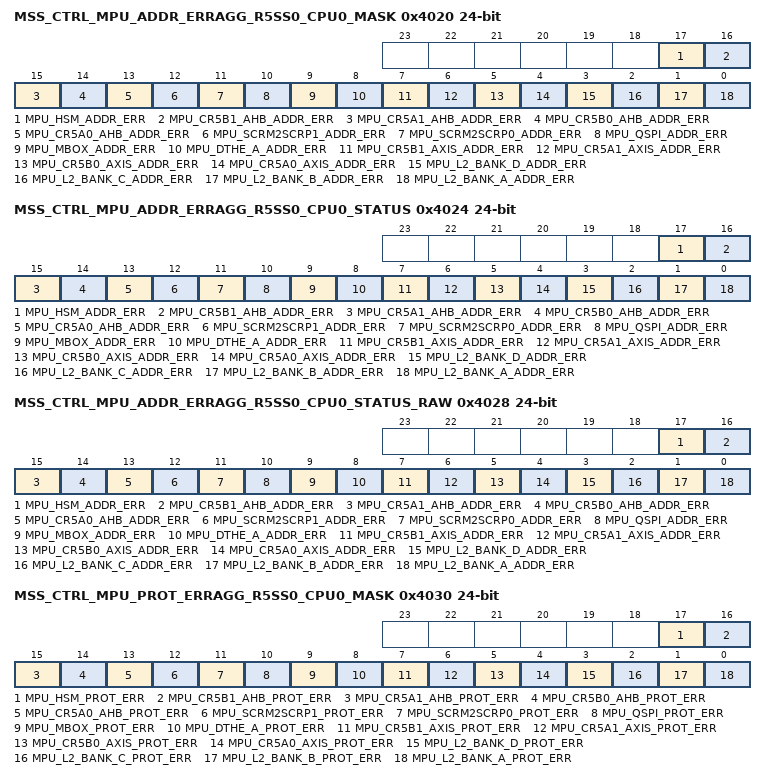
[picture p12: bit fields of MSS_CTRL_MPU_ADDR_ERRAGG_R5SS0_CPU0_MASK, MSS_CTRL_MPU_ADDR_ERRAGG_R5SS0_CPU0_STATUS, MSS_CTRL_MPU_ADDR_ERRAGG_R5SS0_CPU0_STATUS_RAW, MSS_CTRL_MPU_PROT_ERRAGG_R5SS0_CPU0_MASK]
0x4020 MSS_CTRL_MPU_ADDR_ERRAGG_R5SS0_CPU0_MASK 24-bit rw
  [17] MPU_HSM_ADDR_ERR — Mask Error from MPU_ADDR_INTR to aggregated Error MPU_ADDR_INTR_ERRAGG1 : Error is Masked0 : Error is Unmasked
  [16] MPU_CR5B1_AHB_ADDR_ERR — Mask Error from MPU_ADDR_INTR to aggregated Error MPU_ADDR_INTR_ERRAGG1 : Error is Masked0 : Error is Unmasked
  [15] MPU_CR5A1_AHB_ADDR_ERR — Mask Error from MPU_ADDR_INTR to aggregated Error MPU_ADDR_INTR_ERRAGG1 : Error is Masked0 : Error is Unmasked
  [14] MPU_CR5B0_AHB_ADDR_ERR — Mask Error from MPU_ADDR_INTR to aggregated Error MPU_ADDR_INTR_ERRAGG1 : Error is Masked0 : Error is Unmasked
  [13] MPU_CR5A0_AHB_ADDR_ERR — Mask Error from MPU_ADDR_INTR to aggregated Error MPU_ADDR_INTR_ERRAGG1 : Error is Masked0 : Error is Unmasked
  [12] MPU_SCRM2SCRP1_ADDR_ERR — Mask Error from MPU_ADDR_INTR to aggregated Error MPU_ADDR_INTR_ERRAGG1 : Error is Masked0 : Error is Unmasked
  [11] MPU_SCRM2SCRP0_ADDR_ERR — Mask Error from MPU_ADDR_INTR to aggregated Error MPU_ADDR_INTR_ERRAGG1 : Error is Masked0 : Error is Unmasked
  [10] MPU_QSPI_ADDR_ERR — Mask Error from MPU_ADDR_INTR to aggregated Error MPU_ADDR_INTR_ERRAGG1 : Error is Masked0 : Error is Unmasked
  [9] MPU_MBOX_ADDR_ERR — Mask Error from MPU_ADDR_INTR to aggregated Error MPU_ADDR_INTR_ERRAGG1 : Error is Masked0 : Error is Unmasked
  [8] MPU_DTHE_A_ADDR_ERR — Mask Error from MPU_ADDR_INTR to aggregated Error MPU_ADDR_INTR_ERRAGG1 : Error is Masked0 : Error is Unmasked
  [7] MPU_CR5B1_AXIS_ADDR_ERR — Mask Error from MPU_ADDR_INTR to aggregated Error MPU_ADDR_INTR_ERRAGG1 : Error is Masked0 : Error is Unmasked
  [6] MPU_CR5A1_AXIS_ADDR_ERR — Mask Error from MPU_ADDR_INTR to aggregated Error MPU_ADDR_INTR_ERRAGG1 : Error is Masked0 : Error is Unmasked
  [5] MPU_CR5B0_AXIS_ADDR_ERR — Mask Error from MPU_ADDR_INTR to aggregated Error MPU_ADDR_INTR_ERRAGG1 : Error is Masked0 : Error is Unmasked
  [4] MPU_CR5A0_AXIS_ADDR_ERR — Mask Error from MPU_ADDR_INTR to aggregated Error MPU_ADDR_INTR_ERRAGG1 : Error is Masked0 : Error is Unmasked
  [3] MPU_L2_BANK_D_ADDR_ERR — Mask Error from MPU_ADDR_INTR to aggregated Error MPU_ADDR_INTR_ERRAGG1 : Error is Masked0 : Error is Unmasked
  [2] MPU_L2_BANK_C_ADDR_ERR — Mask Error from MPU_ADDR_INTR to aggregated Error MPU_ADDR_INTR_ERRAGG1 : Error is Masked0 : Error is Unmasked
  [1] MPU_L2_BANK_B_ADDR_ERR — Mask Error from MPU_ADDR_INTR to aggregated Error MPU_ADDR_INTR_ERRAGG1 : Error is Masked0 : Error is Unmasked
  [0] MPU_L2_BANK_A_ADDR_ERR — Mask Error from MPU_ADDR_INTR to aggregated Error MPU_ADDR_INTR_ERRAGG1 : Error is Masked0 : Error is Unmasked
0x4024 MSS_CTRL_MPU_ADDR_ERRAGG_R5SS0_CPU0_STATUS 24-bit rw
  [17] MPU_HSM_ADDR_ERR — Status of Error from MPU_ADDR_INTR. Set only if Interupt is unmasked in MPU_ADDR_INTR_ERRAGG_MASKWrie 0x1 to clear this Error.
  [16] MPU_CR5B1_AHB_ADDR_ERR — Status of Error from MPU_ADDR_INTR. Set only if Interupt is unmasked in MPU_ADDR_INTR_ERRAGG_MASKWrie 0x1 to clear this Error.
  [15] MPU_CR5A1_AHB_ADDR_ERR — Status of Error from MPU_ADDR_INTR. Set only if Interupt is unmasked in MPU_ADDR_INTR_ERRAGG_MASKWrie 0x1 to clear this Error.
  [14] MPU_CR5B0_AHB_ADDR_ERR — Status of Error from MPU_ADDR_INTR. Set only if Interupt is unmasked in MPU_ADDR_INTR_ERRAGG_MASKWrie 0x1 to clear this Error.
  [13] MPU_CR5A0_AHB_ADDR_ERR — Status of Error from MPU_ADDR_INTR. Set only if Interupt is unmasked in MPU_ADDR_INTR_ERRAGG_MASKWrie 0x1 to clear this Error.
  [12] MPU_SCRM2SCRP1_ADDR_ERR — Status of Error from MPU_ADDR_INTR. Set only if Interupt is unmasked in MPU_ADDR_INTR_ERRAGG_MASKWrie 0x1 to clear this Error.
  [11] MPU_SCRM2SCRP0_ADDR_ERR — Status of Error from MPU_ADDR_INTR. Set only if Interupt is unmasked in MPU_ADDR_INTR_ERRAGG_MASKWrie 0x1 to clear this Error.
  [10] MPU_QSPI_ADDR_ERR — Status of Error from MPU_ADDR_INTR. Set only if Interupt is unmasked in MPU_ADDR_INTR_ERRAGG_MASKWrie 0x1 to clear this Error.
  [9] MPU_MBOX_ADDR_ERR — Status of Error from MPU_ADDR_INTR. Set only if Interupt is unmasked in MPU_ADDR_INTR_ERRAGG_MASKWrie 0x1 to clear this Error.
  [8] MPU_DTHE_A_ADDR_ERR — Status of Error from MPU_ADDR_INTR. Set only if Interupt is unmasked in MPU_ADDR_INTR_ERRAGG_MASKWrie 0x1 to clear this Error.
  [7] MPU_CR5B1_AXIS_ADDR_ERR — Status of Error from MPU_ADDR_INTR. Set only if Interupt is unmasked in MPU_ADDR_INTR_ERRAGG_MASKWrie 0x1 to clear this Error.
  [6] MPU_CR5A1_AXIS_ADDR_ERR — Status of Error from MPU_ADDR_INTR. Set only if Interupt is unmasked in MPU_ADDR_INTR_ERRAGG_MASKWrie 0x1 to clear this Error.
  [5] MPU_CR5B0_AXIS_ADDR_ERR — Status of Error from MPU_ADDR_INTR. Set only if Interupt is unmasked in MPU_ADDR_INTR_ERRAGG_MASKWrie 0x1 to clear this Error.
  [4] MPU_CR5A0_AXIS_ADDR_ERR — Status of Error from MPU_ADDR_INTR. Set only if Interupt is unmasked in MPU_ADDR_INTR_ERRAGG_MASKWrie 0x1 to clear this Error.
  [3] MPU_L2_BANK_D_ADDR_ERR — Status of Error from MPU_ADDR_INTR. Set only if Interupt is unmasked in MPU_ADDR_INTR_ERRAGG_MASKWrie 0x1 to clear this Error.
  [2] MPU_L2_BANK_C_ADDR_ERR — Status of Error from MPU_ADDR_INTR. Set only if Interupt is unmasked in MPU_ADDR_INTR_ERRAGG_MASKWrie 0x1 to clear this Error.
  [1] MPU_L2_BANK_B_ADDR_ERR — Status of Error from MPU_ADDR_INTR. Set only if Interupt is unmasked in MPU_ADDR_INTR_ERRAGG_MASKWrie 0x1 to clear this Error.
  [0] MPU_L2_BANK_A_ADDR_ERR — Status of Error from MPU_ADDR_INTR. Set only if Interupt is unmasked in MPU_ADDR_INTR_ERRAGG_MASKWrie 0x1 to clear this Error.
0x4028 MSS_CTRL_MPU_ADDR_ERRAGG_R5SS0_CPU0_STATUS_RAW 24-bit rw
  [17] MPU_HSM_ADDR_ERR — Raw Status of Error from MPU_ADDR_INTR. Set irrespective if the Interupt is masked or unmasked in MPU_ADDR_INTR_ERRAGG_MASK
  [16] MPU_CR5B1_AHB_ADDR_ERR — Raw Status of Error from MPU_ADDR_INTR. Set irrespective if the Interupt is masked or unmasked in MPU_ADDR_INTR_ERRAGG_MASK
  [15] MPU_CR5A1_AHB_ADDR_ERR — Raw Status of Error from MPU_ADDR_INTR. Set irrespective if the Interupt is masked or unmasked in MPU_ADDR_INTR_ERRAGG_MASK
  [14] MPU_CR5B0_AHB_ADDR_ERR — Raw Status of Error from MPU_ADDR_INTR. Set irrespective if the Interupt is masked or unmasked in MPU_ADDR_INTR_ERRAGG_MASK
  [13] MPU_CR5A0_AHB_ADDR_ERR — Raw Status of Error from MPU_ADDR_INTR. Set irrespective if the Interupt is masked or unmasked in MPU_ADDR_INTR_ERRAGG_MASK
  [12] MPU_SCRM2SCRP1_ADDR_ERR — Raw Status of Error from MPU_ADDR_INTR. Set irrespective if the Interupt is masked or unmasked in MPU_ADDR_INTR_ERRAGG_MASK
  [11] MPU_SCRM2SCRP0_ADDR_ERR — Raw Status of Error from MPU_ADDR_INTR. Set irrespective if the Interupt is masked or unmasked in MPU_ADDR_INTR_ERRAGG_MASK
  [10] MPU_QSPI_ADDR_ERR — Raw Status of Error from MPU_ADDR_INTR. Set irrespective if the Interupt is masked or unmasked in MPU_ADDR_INTR_ERRAGG_MASK
  [9] MPU_MBOX_ADDR_ERR — Raw Status of Error from MPU_ADDR_INTR. Set irrespective if the Interupt is masked or unmasked in MPU_ADDR_INTR_ERRAGG_MASK
  [8] MPU_DTHE_A_ADDR_ERR — Raw Status of Error from MPU_ADDR_INTR. Set irrespective if the Interupt is masked or unmasked in MPU_ADDR_INTR_ERRAGG_MASK
  [7] MPU_CR5B1_AXIS_ADDR_ERR — Raw Status of Error from MPU_ADDR_INTR. Set irrespective if the Interupt is masked or unmasked in MPU_ADDR_INTR_ERRAGG_MASK
  [6] MPU_CR5A1_AXIS_ADDR_ERR — Raw Status of Error from MPU_ADDR_INTR. Set irrespective if the Interupt is masked or unmasked in MPU_ADDR_INTR_ERRAGG_MASK
  [5] MPU_CR5B0_AXIS_ADDR_ERR — Raw Status of Error from MPU_ADDR_INTR. Set irrespective if the Interupt is masked or unmasked in MPU_ADDR_INTR_ERRAGG_MASK
  [4] MPU_CR5A0_AXIS_ADDR_ERR — Raw Status of Error from MPU_ADDR_INTR. Set irrespective if the Interupt is masked or unmasked in MPU_ADDR_INTR_ERRAGG_MASK
  [3] MPU_L2_BANK_D_ADDR_ERR — Raw Status of Error from MPU_ADDR_INTR. Set irrespective if the Interupt is masked or unmasked in MPU_ADDR_INTR_ERRAGG_MASK
  [2] MPU_L2_BANK_C_ADDR_ERR — Raw Status of Error from MPU_ADDR_INTR. Set irrespective if the Interupt is masked or unmasked in MPU_ADDR_INTR_ERRAGG_MASK
  [1] MPU_L2_BANK_B_ADDR_ERR — Raw Status of Error from MPU_ADDR_INTR. Set irrespective if the Interupt is masked or unmasked in MPU_ADDR_INTR_ERRAGG_MASK
  [0] MPU_L2_BANK_A_ADDR_ERR — Raw Status of Error from MPU_ADDR_INTR. Set irrespective if the Interupt is masked or unmasked in MPU_ADDR_INTR_ERRAGG_MASK
0x4030 MSS_CTRL_MPU_PROT_ERRAGG_R5SS0_CPU0_MASK 24-bit rw
  [17] MPU_HSM_PROT_ERR — Mask Error from MPU_PROT_INTR to aggregated Error MPU_PROT_INTR_ERRAGG1 : Error is Masked0 : Error is Unmasked
  [16] MPU_CR5B1_AHB_PROT_ERR — Mask Error from MPU_PROT_INTR to aggregated Error MPU_PROT_INTR_ERRAGG1 : Error is Masked0 : Error is Unmasked
  [15] MPU_CR5A1_AHB_PROT_ERR — Mask Error from MPU_PROT_INTR to aggregated Error MPU_PROT_INTR_ERRAGG1 : Error is Masked0 : Error is Unmasked
  [14] MPU_CR5B0_AHB_PROT_ERR — Mask Error from MPU_PROT_INTR to aggregated Error MPU_PROT_INTR_ERRAGG1 : Error is Masked0 : Error is Unmasked
  [13] MPU_CR5A0_AHB_PROT_ERR — Mask Error from MPU_PROT_INTR to aggregated Error MPU_PROT_INTR_ERRAGG1 : Error is Masked0 : Error is Unmasked
  [12] MPU_SCRM2SCRP1_PROT_ERR — Mask Error from MPU_PROT_INTR to aggregated Error MPU_PROT_INTR_ERRAGG1 : Error is Masked0 : Error is Unmasked
  [11] MPU_SCRM2SCRP0_PROT_ERR — Mask Error from MPU_PROT_INTR to aggregated Error MPU_PROT_INTR_ERRAGG1 : Error is Masked0 : Error is Unmasked
  [10] MPU_QSPI_PROT_ERR — Mask Error from MPU_PROT_INTR to aggregated Error MPU_PROT_INTR_ERRAGG1 : Error is Masked0 : Error is Unmasked
  [9] MPU_MBOX_PROT_ERR — Mask Error from MPU_PROT_INTR to aggregated Error MPU_PROT_INTR_ERRAGG1 : Error is Masked0 : Error is Unmasked
  [8] MPU_DTHE_A_PROT_ERR — Mask Error from MPU_PROT_INTR to aggregated Error MPU_PROT_INTR_ERRAGG1 : Error is Masked0 : Error is Unmasked
  [7] MPU_CR5B1_AXIS_PROT_ERR — Mask Error from MPU_PROT_INTR to aggregated Error MPU_PROT_INTR_ERRAGG1 : Error is Masked0 : Error is Unmasked
  [6] MPU_CR5A1_AXIS_PROT_ERR — Mask Error from MPU_PROT_INTR to aggregated Error MPU_PROT_INTR_ERRAGG1 : Error is Masked0 : Error is Unmasked
  [5] MPU_CR5B0_AXIS_PROT_ERR — Mask Error from MPU_PROT_INTR to aggregated Error MPU_PROT_INTR_ERRAGG1 : Error is Masked0 : Error is Unmasked
  [4] MPU_CR5A0_AXIS_PROT_ERR — Mask Error from MPU_PROT_INTR to aggregated Error MPU_PROT_INTR_ERRAGG1 : Error is Masked0 : Error is Unmasked
  [3] MPU_L2_BANK_D_PROT_ERR — Mask Error from MPU_PROT_INTR to aggregated Error MPU_PROT_INTR_ERRAGG1 : Error is Masked0 : Error is Unmasked
  [2] MPU_L2_BANK_C_PROT_ERR — Mask Error from MPU_PROT_INTR to aggregated Error MPU_PROT_INTR_ERRAGG1 : Error is Masked0 : Error is Unmasked
  [1] MPU_L2_BANK_B_PROT_ERR — Mask Error from MPU_PROT_INTR to aggregated Error MPU_PROT_INTR_ERRAGG1 : Error is Masked0 : Error is Unmasked
  [0] MPU_L2_BANK_A_PROT_ERR — Mask Error from MPU_PROT_INTR to aggregated Error MPU_PROT_INTR_ERRAGG1 : Error is Masked0 : Error is Unmasked
